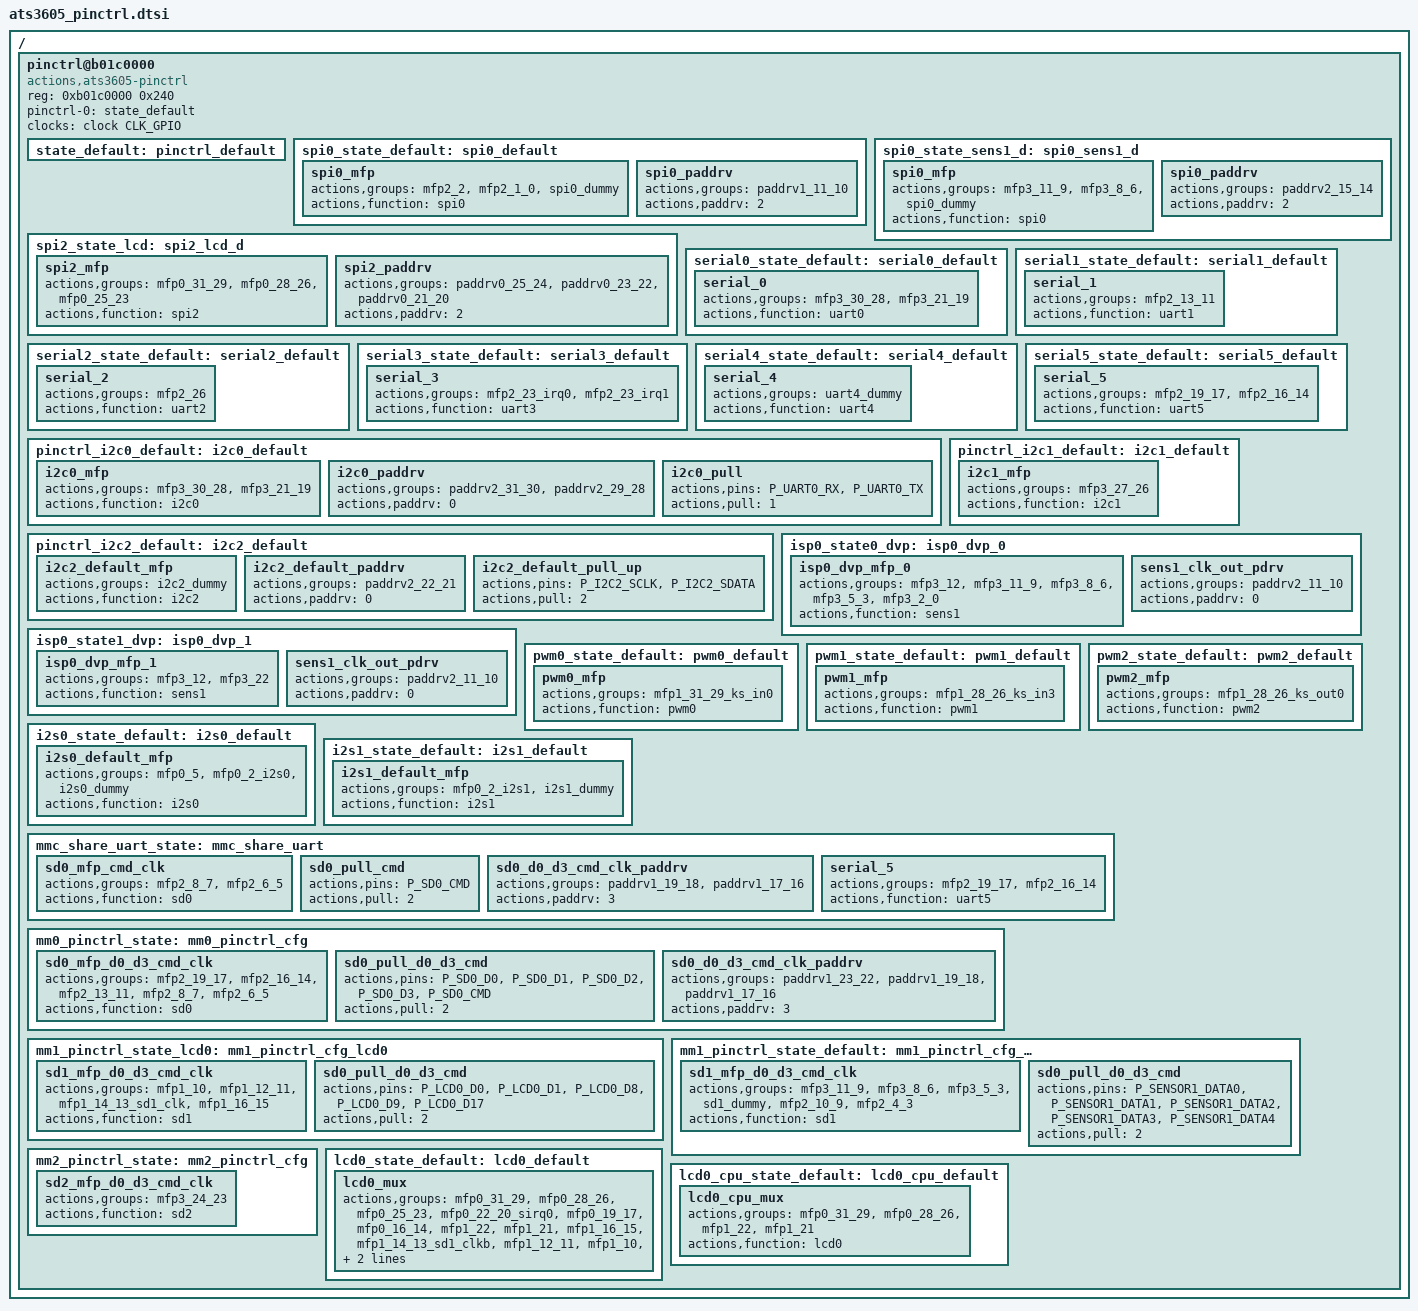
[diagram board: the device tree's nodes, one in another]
/*
 * Copyright (C) 2014 Actions Semi. Inc
 *
 * This program is free software; you can redistribute it and/or
 * modify it under the terms of the GNU General Public License as
 * published by the Free Software Foundation version 2.
 *
 * This program is distributed "as is" WITHOUT ANY WARRANTY of any
 * kind, whether express or implied; without even the implied warranty
 * of MERCHANTABILITY or FITNESS FOR A PARTICULAR PURPOSE.  See the
 * GNU General Public License for more details.
 */

/ {

	pinctrl@b01c0000 {
		compatible = "actions,ats3605-pinctrl";
		reg = <0xb01c0000  0x240>;

		pinctrl-names = "default";
		pinctrl-0 = <&state_default>;
		clocks = <&clock CLK_GPIO>;
		clock-names = "mfp";

		state_default: pinctrl_default {
		};
	
		spi0_state_default: spi0_default {
			spi0_mfp {
				actions,groups = "mfp2_2","mfp2_1_0", "spi0_dummy";
				actions,function = "spi0";
			};
			spi0_paddrv {
				actions,groups = "paddrv1_11_10";
				actions,paddrv = <2>;/*level 2*/
			};
			//spi0_pull {
				//actions,pins = "P_I2C0_SCLK", "P_I2C0_SDATA";
				//actions,schmitt  = "P_I2C0_SCLK", "P_I2C0_SDATA";
				//actions,pull = <0>;
			//};
		};

		spi0_state_sens1_d: spi0_sens1_d {
			spi0_mfp {
				actions,groups = "mfp3_11_9","mfp3_8_6", "spi0_dummy";
				actions,function = "spi0";
			};
			spi0_paddrv {
				actions,groups = "paddrv2_15_14";
				actions,paddrv = <2>;/*level 2*/
			};
		};

		spi2_state_lcd: spi2_lcd_d {
			spi2_mfp {
				actions,groups = "mfp0_31_29","mfp0_28_26", "mfp0_25_23";
				actions,function = "spi2";
			};
			spi2_paddrv {
				actions,groups = "paddrv0_25_24","paddrv0_23_22","paddrv0_21_20";
				actions,paddrv = <2>;/*level 2*/
			};
		};

		serial0_state_default: serial0_default{
			serial_0{
				actions,groups = "mfp3_30_28","mfp3_21_19";
				actions,function = "uart0";
			};
		};

		serial1_state_default: serial1_default{
			serial_1{
				actions,groups = "mfp2_13_11";
				actions,function = "uart1";
			};
		};

		serial2_state_default: serial2_default{
			serial_2{
				actions,groups = "mfp2_26";
				actions,function = "uart2";
			};
		};

		serial3_state_default: serial3_default{
			serial_3{
				actions,groups = "mfp2_23_irq0","mfp2_23_irq1";
				actions,function = "uart3";
			};
		};

		serial4_state_default: serial4_default{
			serial_4{
				actions,groups = "uart4_dummy";
				actions,function = "uart4";
			};
		};

		serial5_state_default: serial5_default{
			serial_5{
				actions,groups = "mfp2_19_17","mfp2_16_14";
				actions,function = "uart5";
			};
		};


		pinctrl_i2c0_default: i2c0_default {
			i2c0_mfp {
				actions,groups = "mfp3_30_28", "mfp3_21_19";
				actions,function = "i2c0";
			};
			i2c0_paddrv {
				actions,groups = "paddrv2_31_30", "paddrv2_29_28";
				actions,paddrv = <0>;/*level 1*/
			};
			i2c0_pull {
				actions,pins = "P_UART0_RX", "P_UART0_TX";
				actions,pull = <1>;
			};
		};

		pinctrl_i2c1_default: i2c1_default {
			i2c1_mfp {
				actions,groups = "mfp3_27_26";
				actions,function = "i2c1";
			};
			//i2c1_paddrv {
			//	actions,groups = "paddrv2_9_8";
			//	actions,paddrv = <0>;/*level 1*/
			//};
			//i2c1_pull {
			//	actions,pins = "P_NAND_CEB2", "P_NAND_CEB3";
			//	actions,pull = <1>;
			//};
		};

		pinctrl_i2c2_default: i2c2_default {/* i2c2 use default pin*/
			i2c2_default_mfp {
				actions,groups = "i2c2_dummy";
				actions,function = "i2c2";
			};

			i2c2_default_paddrv {
				actions,groups = "paddrv2_22_21";
				actions,paddrv = <0>;/*level 1*/
			};

			i2c2_default_pull_up {
				actions,pins = "P_I2C2_SCLK","P_I2C2_SDATA";
				actions,pull = <2>; /*pull up*/
			};
		};

		/* the format of isp state name: channel + bus type(pin function) */
		isp0_state0_dvp: isp0_dvp_0 {
			isp0_dvp_mfp_0 {
				actions,groups = "mfp3_12", "mfp3_11_9", "mfp3_8_6", "mfp3_5_3", "mfp3_2_0";
				actions,function = "sens1";
			};
			sens1_clk_out_pdrv{
				 actions,groups = "paddrv2_11_10";
				 actions,paddrv = <0>;/*level 1 ,range :0~2*/
			};
		};
		isp0_state1_dvp: isp0_dvp_1 {
			isp0_dvp_mfp_1 {
				actions,groups = "mfp3_12", "mfp3_22";
				actions,function = "sens1";
			};
			sens1_clk_out_pdrv{
				 actions,groups = "paddrv2_11_10";
				 actions,paddrv = <0>;/*level 1 ,range :0~2*/
			};
		};

		pwm0_state_default: pwm0_default {
			pwm0_mfp {
				actions,groups = "mfp1_31_29_ks_in0";
				actions,function = "pwm0";
			};
		};

		pwm1_state_default: pwm1_default {
			pwm1_mfp {
				actions,groups = "mfp1_28_26_ks_in3";
				actions,function = "pwm1";
			};
		};
		pwm2_state_default: pwm2_default {
			pwm2_mfp {
				actions,groups = "mfp1_28_26_ks_out0";
				actions,function = "pwm2";
			};
		};
	
		i2s0_state_default: i2s0_default {
			i2s0_default_mfp {
				actions,groups = "mfp0_5", "mfp0_2_i2s0", "i2s0_dummy";
				actions,function = "i2s0";
			};
		};

		i2s1_state_default: i2s1_default {
			i2s1_default_mfp {
				actions,groups = "mfp0_2_i2s1", "i2s1_dummy";
				actions,function = "i2s1";
			};
		};

		mmc_share_uart_state: mmc_share_uart {
			sd0_mfp_cmd_clk {
				actions,groups = "mfp2_8_7", "mfp2_6_5";
				actions,function = "sd0";
			};

			sd0_pull_cmd {
				actions,pins = "P_SD0_CMD";
				actions,pull = <2>;
			};

			sd0_d0_d3_cmd_clk_paddrv  {
				actions,groups  = "paddrv1_19_18","paddrv1_17_16";
				actions,paddrv  = <3>; /*level 3锛?~3*/
			};

			serial_5 {
				actions,groups = "mfp2_19_17","mfp2_16_14";
				actions,function = "uart5";
			};
		};

		mm0_pinctrl_state: mm0_pinctrl_cfg {
			sd0_mfp_d0_d3_cmd_clk {
				actions,groups = "mfp2_19_17", "mfp2_16_14", "mfp2_13_11", "mfp2_8_7", "mfp2_6_5";
				actions,function = "sd0";
			};

			sd0_pull_d0_d3_cmd {
				actions,pins = "P_SD0_D0", "P_SD0_D1", "P_SD0_D2", "P_SD0_D3", "P_SD0_CMD";
				actions,pull = <2>;
			};

			sd0_d0_d3_cmd_clk_paddrv  {
				actions,groups  = "paddrv1_23_22","paddrv1_19_18","paddrv1_17_16";
				actions,paddrv  = <3>; /*level 3,0~3*/
			};
		};


		mm1_pinctrl_state_lcd0: mm1_pinctrl_cfg_lcd0 {
			sd1_mfp_d0_d3_cmd_clk {
				actions,groups = "mfp1_10", "mfp1_12_11", "mfp1_14_13_sd1_clk", "mfp1_16_15";
				actions,function = "sd1";
			};

			sd0_pull_d0_d3_cmd {
				actions,pins = "P_LCD0_D0", "P_LCD0_D1", "P_LCD0_D8", "P_LCD0_D9",  "P_LCD0_D17";
				actions,pull = <2>;
			};

		};
		mm1_pinctrl_state_default: mm1_pinctrl_cfg_default {
			sd1_mfp_d0_d3_cmd_clk {
				actions,groups = "mfp3_11_9", "mfp3_8_6", "mfp3_5_3", "sd1_dummy","mfp2_10_9", "mfp2_4_3";
				actions,function = "sd1";
			};

			sd0_pull_d0_d3_cmd {
				actions,pins = "P_SENSOR1_DATA0", "P_SENSOR1_DATA1", "P_SENSOR1_DATA2", "P_SENSOR1_DATA3", "P_SENSOR1_DATA4";
				actions,pull = <2>;
			};

		};
		mm2_pinctrl_state: mm2_pinctrl_cfg {
			sd2_mfp_d0_d3_cmd_clk {
				actions,groups = "mfp3_24_23";
				actions,function = "sd2";
			};
		};
		
		lcd0_state_default: lcd0_default {
			lcd0_mux {
				actions,groups = "mfp0_31_29", "mfp0_28_26", "mfp0_25_23", "mfp0_22_20_sirq0", "mfp0_19_17", "mfp0_16_14", "mfp1_22", "mfp1_21", "mfp1_16_15", "mfp1_14_13_sd1_clkb", "mfp1_12_11", "mfp1_10", "mfp1_9";
				actions,function = "lcd0";
			};
		};

	
		lcd0_cpu_state_default: lcd0_cpu_default {
			lcd0_cpu_mux {
				actions,groups = "mfp0_31_29", "mfp0_28_26", "mfp1_22", "mfp1_21";
				actions,function = "lcd0";
			};
		};

	};
};
